VERSION ""

NS_ :

BS_:

BU_: Autobox Controller

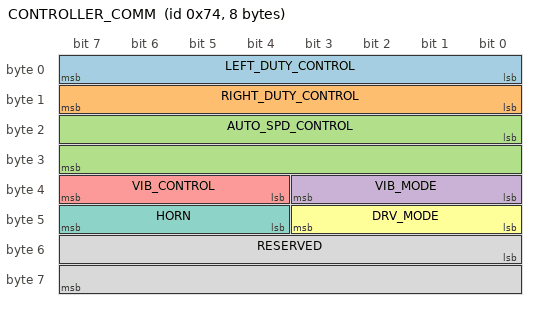
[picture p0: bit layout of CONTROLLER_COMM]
BO_ 116 CONTROLLER_COMM: 8 Controller
 SG_ LEFT_DUTY_CONTROL : 0|8@1- (1,0) [0|100] "%"  Autobox
 SG_ RIGHT_DUTY_CONTROL : 8|8@1- (1,0) [0|100] "%"  Autobox
 SG_ AUTO_SPD_CONTROL : 16|16@1- (1,0) [-1000|1000] "#"  Autobox
 SG_ VIB_MODE : 32|4@1+ (1,0) [0|15] "#"  Autobox
 SG_ VIB_CONTROL : 36|4@1+ (1,0) [0|15] "#"  Autobox
 SG_ DRV_MODE : 40|4@1+ (1,0) [0|15] "#"  Autobox
 SG_ HORN : 44|4@1+ (1,0) [0|15] "#"  Autobox
 SG_ RESERVED : 48|16@1+ (1,0) [0|65535] "N/A"  Autobox

CM_ SG_ 116 VIB_MODE "0: 중립, 1: 저진동, 2: 고진동
";
CM_ SG_ 116 DRV_MODE "0: 거북이, 1:상차, 2:경사전진, 3:경사후진, 4:토끼
";
CM_ SG_ 116 HORN "0: 꺼짐, 1: 켜짐
";
BA_DEF_  "BusType" STRING ;
BA_DEF_DEF_  "BusType" "";
BA_ "BusType" "CAN";
